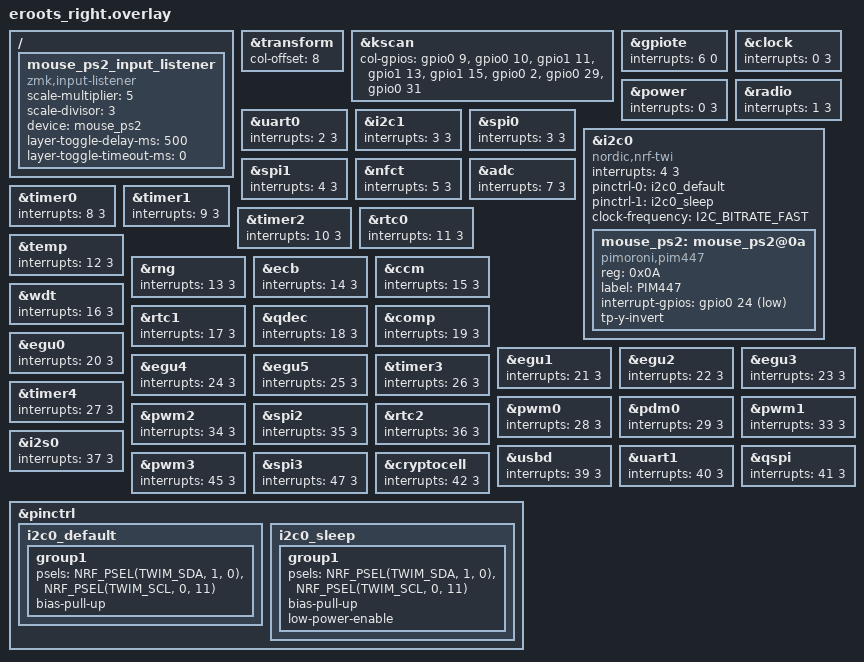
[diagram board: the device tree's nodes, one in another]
#include "eroots.dtsi"


#define HAS_MOUSE_KEYS
#define HAS_MOUSE_TP

#define ZMK_MOUSE_DEFAULT_MOVE_VAL 600  // 600
#define ZMK_MOUSE_DEFAULT_SCRL_VAL 10    // 10


&transform {
    col-offset = <8>;
};
&kscan {
    col-gpios = <&gpio0  9 GPIO_ACTIVE_HIGH>,
                <&gpio0 10 GPIO_ACTIVE_HIGH>,
                <&gpio1 11 GPIO_ACTIVE_HIGH>,
                <&gpio1 13 GPIO_ACTIVE_HIGH>,
                <&gpio1 15 GPIO_ACTIVE_HIGH>,
                <&gpio0  2 GPIO_ACTIVE_HIGH>,
                <&gpio0 29 GPIO_ACTIVE_HIGH>,
                <&gpio0 31 GPIO_ACTIVE_HIGH>;
};

// gpiote should have the highest interrupt priority (0)
&gpiote {
    interrupts = < 6 0 >;
};

// All other priorities should be two levels lower than their defaults
// (which is usually 1 and should be demoted to 3)
&clock {
    interrupts = < 0 3 >;
};

&power {
    interrupts = < 0 3 >;
};

&radio {
    interrupts = < 1 3 >;
};

&uart0 {
    interrupts = < 2 3 >;
};

&i2c1 {
    interrupts = < 3 3 >;
};

&spi0 {
    interrupts = < 3 3 >;
};


&i2c0 {
    interrupts = < 4 3 >;
};

&spi1 {
    interrupts = < 4 3 >;
};

&nfct {
    interrupts = < 5 3 >;
};

&adc {
    interrupts = < 7 3 >;
};

&timer0 {
    interrupts = < 8 3 >;
};

&timer1 {
    interrupts = < 9 3 >;
};

&timer2 {
    interrupts = < 10 3 >;
};

&rtc0 {
    interrupts = < 11 3 >;
};

&temp {
    interrupts = < 12 3 >;
};

&rng {
    interrupts = < 13 3 >;
};

&ecb {
    interrupts = < 14 3 >;
};

&ccm {
    interrupts = < 15 3 >;
};

&wdt {
    interrupts = < 16 3 >;
};

&rtc1 {
    interrupts = < 17 3 >;
};

&qdec {
    interrupts = < 18 3 >;
};

&comp {
    interrupts = < 19 3 >;
};

&egu0 {
    interrupts = < 20 3 >;
};

&egu1 {
    interrupts = < 21 3 >;
};

&egu2 {
    interrupts = < 22 3 >;
};

&egu3 {
    interrupts = < 23 3 >;
};

&egu4 {
    interrupts = < 24 3 >;
};

&egu5 {
    interrupts = < 25 3 >;
};

&timer3 {
    interrupts = < 26 3 >;
};

&timer4 {
    interrupts = < 27 3 >;
};

&pwm0 {
    interrupts = < 28 3 >;
};

&pdm0 {
    interrupts = < 29 3 >;
};

&pwm1 {
    interrupts = < 33 3 >;
};

&pwm2 {
    interrupts = < 34 3 >;
};

&spi2 {
    interrupts = < 35 3 >;
};

&rtc2 {
    interrupts = < 36 3 >;
};

&i2s0 {
    interrupts = < 37 3 >;
};

&usbd {
    interrupts = < 39 3 >;
};

&uart1 {
    interrupts = < 40 3 >;
};

&qspi {
    interrupts = < 41 3 >;
};

&pwm3 {
    interrupts = < 45 3 >;
};

&spi3 {
    interrupts = < 47 3 >;
};

&cryptocell {
    interrupts = < 42 3 >;
};

&pinctrl {
    i2c0_default: i2c0_default {
		group1 {
			psels = <NRF_PSEL(TWIM_SDA, 1, 0)>,
					<NRF_PSEL(TWIM_SCL, 0, 11)>;
            bias-pull-up;
		};
	};

	i2c0_sleep: i2c0_sleep {
		group1 {
			psels = <NRF_PSEL(TWIM_SDA, 1, 0)>,
					<NRF_PSEL(TWIM_SCL, 0, 11)>;
            bias-pull-up;
			low-power-enable;
		};
	};
};

&i2c0 {
    status = "okay";

    compatible = "nordic,nrf-twi";
    pinctrl-0 = <&i2c0_default>;
    pinctrl-1 = <&i2c0_sleep>;
    pinctrl-names = "default", "sleep";
    clock-frequency = <I2C_BITRATE_FAST>;

    mouse_ps2: mouse_ps2@0a {
        compatible = "pimoroni,pim447";
        reg = <0x0A>;
        label = "PIM447";
        interrupt-gpios = <&gpio0 24 (GPIO_ACTIVE_LOW | GPIO_PULL_UP)>;
		status = "okay";
    };

};

/ {

    mouse_ps2_input_listener: mouse_ps2_input_listener {
        compatible = "zmk,input-listener";
        status = "okay";
        
        scale-multiplier = <5>;
        scale-divisor = <3>;

        device = <&mouse_ps2>;
    };
};



#ifdef HAS_MOUSE_TP
  #include <dt-bindings/zmk/mouse.h>
  #include <dt-bindings/zmk/mouse_settings.h>
  #include <behaviors/mouse_keys.dtsi>
  #include <behaviors/mouse_setting.dtsi>

 /*
  * Key Behaviors to adjust settings
  */

  // They key codes below can be used to adjust the TP settings at runtime
  // without needing to recompile the firmware.
  //
  // The values will be logged and saved in the config on the controller flash
  // after 60s (CONFIG_ZMK_SETTINGS_SAVE_DEBOUNCE).
  //
  // On boot the settings will be restored again.
  //
  // If you prefer a more explicit way of configuration, you can also hardcode
  // these settings in `&mouse_ps2`.
  //
  // If you set these settings in `&mouse_ps2`, you will still be able to
  // adjust the values during runtime with these key codes, but after
  // restarting the board the values in `&mouse_ps2` will be restored and not
  // the ones stored in the flash using the key codes.


  // How sensitive the trackpoint is
  #define U_MSS_TP_S_I &mms MS_TP_SENSITIVITY_INCR
  #define U_MSS_TP_S_D &mms MS_TP_SENSITIVITY_DECR


  // The maximum speed the trackpoint will accelerate to
  #define U_MSS_TP_V6_I &mms MS_TP_VALUE6_INCR
  #define U_MSS_TP_V6_D &mms MS_TP_VALUE6_DECR


  // I am not quite sure tbh... default seems fine.
  #define U_MSS_TP_NI_I &mms MS_TP_NEG_INERTIA_INCR
  #define U_MSS_TP_NI_D &mms MS_TP_NEG_INERTIA_DECR


  // How hard you have to press to activate the "Press To Select" feature that
  // lets you tap or press on the trackpoint to click.
  //
  // Not all trackpoints support it and you have to enable
  // `tp-press-to-select;` in `&mouse_ps2` first.
  #define U_MSS_TP_PT_I &mms MS_TP_PTS_THRESHOLD_INCR
  #define U_MSS_TP_PT_D &mms MS_TP_PTS_THRESHOLD_DECR


  // If you mess up the settings, you can use this key code to clear the
  // settings from flash and re-set the default values on the TP.
  //
  // Make sure to wait at least CONFIG_ZMK_SETTINGS_SAVE_DEBOUNCE seconds (60
  // by default) before restarting the board to ensure the settings are
  // written to flash storage.
  #define U_MSS_RESET   &mms MS_RESET


  // If you prefer to set the settings in `&mouse_ps2`, you can use the key
  // codes above to find the settings you like the most and then press this
  // key code to output the settings to the log.
  //
  // Then you can add those values to `&mouse_ps2`
  #define U_MSS_LOG     &mms MS_LOG


  // Only apply these settings on the side that has the TP connected
  // (usually the right side)

   /*
    * Input Listener Config
    */

    &mouse_ps2_input_listener {

      // Adjust pointing device axes.
      // This adjusts the values inside the zmk driver. Some
      // trackpoints also allow you to adjust it in their firmware. Check
      // the driver options below for more info.
      // xy-swap;
      // x-invert;
      // y-invert;

      // Set the layer that should automatically activate when the mouse is
      // moving.
      // layer-toggle = <MOUSE>;

      // How long the mouse needs to move for before the layer is activated (to
      // avoid accidental activations while typing) (Default: 250)
      layer-toggle-delay-ms = <500>;

      // How long to wait, after the last mouse movement, before deactivating
      // the layer (Default: 500)
      layer-toggle-timeout-ms = <0>;
    };

   /*
    * Mouse Driver Settings
    */

    &mouse_ps2 {

      // How sensitive the TP is (Default: 128)
      // tp-sensitivity = <128>;


      // The maximum mouse movement speed the TP will accelarate to
      // (Default: 97)
      // tp-val6-upper-speed = <97>;


      // Negative Inertia (Default: 6)
      // Makes the TP feel more responsive and "overshoot" less.
      // tp-neg-inertia = <6>;


      // Enable clicking by tapping on the TP.
      // Not all TPs support this.
      // tp-press-to-select;
      // tp-press-to-select-threshold = <10>;


      // Adjust axis settings on the TP
      // Works only on some trackpoints, but may be properly considered by the
      // trackpoint's acceleration features (which may or may not have an
      // impact).
      //
      // Alternatively consider achieving the same effect using the
      //  `input-listener` settings below.
      // tp-xy-swap;
      // tp-x-invert;
      tp-y-invert;


      // Set sampling rate
      //
      // The frequency at which the mouse samples and sends data (in hz).
      // The default rate is 100. You can try lowering it if you experience
      // connection errors.
      //
      // Higher values than 100 are no improvement in my experience, but will
      // increase battery life and potentially errors in transmissions.
      //
      // These values are allowed: 10,20,40,60,80,100,200
      // sampling-rate = <60>;


      // Disables clicking.
      // Useful when using the PS2 GPIO driver that is prone to
      // erros in transmissions to reduce accidental clicks.
      // disable-clicking;


      // Enable scroll wheel
      // For mouse devices supporting the Intellimouse extension. Not relevant
      // for trackpoints
      // scroll-mode;

    };

    // Enable PS/2 Mouse Devices
    // In `your_keyboard_right.overlay` all devices have `status = "disabled"`.
    // So,they are never compiled into the firmware.
    //
    // Here we enable them, but we do it within the #ifdef HAS_MOUSE_TP code
    // block, which prevents compilation and potential build errors when we
    // undefine HAS_MOUSE_TP in corne_tp.keymap
    &mouse_ps2  {
      status = "okay";
    };

    &mouse_ps2_input_listener {
      status = "okay";
    };


#endif  // HAS_MOUSE_TP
